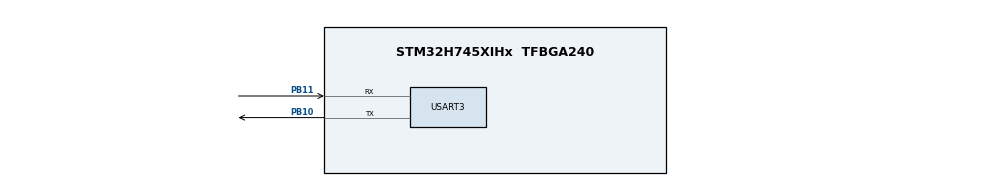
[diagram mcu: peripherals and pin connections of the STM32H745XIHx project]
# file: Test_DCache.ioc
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CortexM4.IPs=FATFS_M4\:I,FREERTOS_M4\:I,IWDG2\:I,RCC,USB_DEVICE_M4\:I,USB_HOST_M4\:I,WWDG2\:I,DMA,BDMA,MDMA,NVIC2\:I,SAI2\:I,LTDC\:I,SAI4\:I,DEBUG,PDM2PCM_M4\:I,PWR,RESMGR_UTILITY,SYS_M4\:I,CORTEX_M4\:I,OPENAMP_M4\:I,VREFBUF,GPIO
CortexM7.IPs=FATFS_M7\:I,FREERTOS_M7\:I,IWDG1\:I,RCC\:I,USB_DEVICE_M7\:I,USB_HOST_M7\:I,WWDG1\:I,DMA\:I,BDMA\:I,MDMA\:I,NVIC1\:I,CORTEX_M7\:I,DEBUG\:I,PDM2PCM_M7\:I,PWR\:I,RESMGR_UTILITY\:I,SYS\:I,OPENAMP_M7\:I,VREFBUF\:I,GPIO\:I,USART3\:I
Dma.MEMTOMEM.0.Direction=DMA_MEMORY_TO_MEMORY
Dma.MEMTOMEM.0.EventEnable=DISABLE
Dma.MEMTOMEM.0.FIFOMode=DMA_FIFOMODE_ENABLE
Dma.MEMTOMEM.0.FIFOThreshold=DMA_FIFO_THRESHOLD_FULL
Dma.MEMTOMEM.0.Instance=DMA1_Stream0
Dma.MEMTOMEM.0.MemBurst=DMA_MBURST_SINGLE
Dma.MEMTOMEM.0.MemDataAlignment=DMA_MDATAALIGN_WORD
Dma.MEMTOMEM.0.MemInc=DMA_MINC_ENABLE
Dma.MEMTOMEM.0.Mode=DMA_NORMAL
Dma.MEMTOMEM.0.PeriphBurst=DMA_PBURST_SINGLE
Dma.MEMTOMEM.0.PeriphDataAlignment=DMA_PDATAALIGN_WORD
Dma.MEMTOMEM.0.PeriphInc=DMA_PINC_ENABLE
Dma.MEMTOMEM.0.Polarity=HAL_DMAMUX_REQ_GEN_RISING
Dma.MEMTOMEM.0.Priority=DMA_PRIORITY_HIGH
Dma.MEMTOMEM.0.RequestNumber=1
Dma.MEMTOMEM.0.SignalID=NONE
Dma.MEMTOMEM.0.SyncEnable=DISABLE
Dma.MEMTOMEM.0.SyncPolarity=HAL_DMAMUX_SYNC_NO_EVENT
Dma.MEMTOMEM.0.SyncRequestNumber=1
Dma.MEMTOMEM.0.SyncSignalID=NONE
Dma.Request0=MEMTOMEM
Mcu.Family=STM32H7
Mcu.Name=STM32H745XIHx
Mcu.Package=TFBGA240
NVIC1.PriorityGroup=NVIC_PRIORITYGROUP_4
NVIC2.PriorityGroup=NVIC_PRIORITYGROUP_4
PB10.Mode=Asynchronous
PB10.PinAttribute=CortexM7
PB10.Signal=USART3_TX
PB11.Mode=Asynchronous
PB11.PinAttribute=CortexM7
PB11.Signal=USART3_RX
PH0-OSC_IN\ (PH0).Mode=HSE-External-Clock-Source
PH0-OSC_IN\ (PH0).PinAttribute=Free
PH0-OSC_IN\ (PH0).Signal=RCC_OSC_IN
ProjectManager.HeapSize=M4-0x200,M7-0x200
ProjectManager.StackSize=M4-0x400,M7-0x400
ProjectManager.TargetToolchain=STM32CubeIDE
RCC.ADCFreq_Value=50390625
RCC.APB1Freq_Value=25000000
RCC.APB2Freq_Value=25000000
RCC.APB3Freq_Value=25000000
RCC.APB4Freq_Value=25000000
RCC.CortexFreq_Value=25000000
RCC.DIVM1=23
RCC.DIVN1=177
RCC.DIVN3=192
RCC.DIVQ1=4
RCC.DIVR1=4
RCC.HCLKFreq_Value=25000000
RCC.PLL2FRACN=0
RCC.PLL3FRACN=0
RCC.PLLFRACN=0
RCC.PLLSourceVirtual=RCC_PLLSOURCE_HSE
RCC.PWR_Regulator_Voltage_Scale=PWR_REGULATOR_VOLTAGE_SCALE2
RCC.SYSCLKFreq_VALUE=25000000
RCC.SYSCLKSource=RCC_SYSCLKSOURCE_HSE
RCC.SupplySource=PWR_DIRECT_SMPS_SUPPLY
RCC.USBFreq_Value=48097826.086956516
USART3.VirtualMode-Asynchronous=VM_ASYNC
VP_SYS_M4_VS_Systick.Mode=SysTick
board=STM32H745I-DISCO

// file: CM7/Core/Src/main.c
/* USER CODE BEGIN Header */
/**
  ******************************************************************************
  * @file           : main.c
  * @brief          : Main program body
  ******************************************************************************
  * @attention
  *
  * Copyright (c) 2025 STMicroelectronics.
  * All rights reserved.
  *
  * This software is licensed under terms that can be found in the LICENSE file
  * in the root directory of this software component.
  * If no LICENSE file comes with this software, it is provided AS-IS.
  *
  ******************************************************************************
  */
/* USER CODE END Header */
#include "main.h"

/* USER CODE BEGIN Includes */
#include <stdio.h>
/* USER CODE END Includes */

/* USER CODE BEGIN PD */

#ifndef HSEM_ID_0
#define HSEM_ID_0 (0U) /* HW semaphore 0*/
#endif

/* USER CODE END PD */

/* USER CODE BEGIN PM */
#define BUFFER_SIZE 128
uint32_t src_buffer[BUFFER_SIZE];
uint32_t dst_buffer[BUFFER_SIZE];
/* USER CODE END PM */

UART_HandleTypeDef huart3;

DMA_HandleTypeDef hdma_memtomem_dma1_stream0;

void SystemClock_Config(void);
static void MX_GPIO_Init(void);
static void MX_DMA_Init(void);
static void MX_USART3_UART_Init(void);

/* USER CODE BEGIN 0 */
void fill_src_buffer(void)
{
    for (int i = 0; i < BUFFER_SIZE; i++)
        src_buffer[i] = i;
}
/* USER CODE END 0 */

int main(void)
{

/* USER CODE BEGIN Boot_Mode_Sequence_0 */
  //int32_t timeout;
/* USER CODE END Boot_Mode_Sequence_0 */

/* USER CODE BEGIN Boot_Mode_Sequence_1 */
  /* Wait until CPU2 boots and enters in stop mode or timeout*/
/*  timeout = 0xFFFF;
  while((__HAL_RCC_GET_FLAG(RCC_FLAG_D2CKRDY) != RESET) && (timeout-- > 0));
  if ( timeout < 0 )
  {
  Error_Handler();
  }*/
/* USER CODE END Boot_Mode_Sequence_1 */
  /* MCU Configuration--------------------------------------------------------*/

  /* Reset of all peripherals, Initializes the Flash interface and the Systick. */
  HAL_Init();

  /* Configure the system clock */
  SystemClock_Config();
/* USER CODE BEGIN Boot_Mode_Sequence_2 */
/* When system initialization is finished, Cortex-M7 will release Cortex-M4 by means of
HSEM notification */
/*HW semaphore Clock enable*/
__HAL_RCC_HSEM_CLK_ENABLE();
/*Take HSEM */
HAL_HSEM_FastTake(HSEM_ID_0);
/*Release HSEM in order to notify the CPU2(CM4)*/
HAL_HSEM_Release(HSEM_ID_0,0);
/* wait until CPU2 wakes up from stop mode */
/*timeout = 0xFFFF;
while((__HAL_RCC_GET_FLAG(RCC_FLAG_D2CKRDY) == RESET) && (timeout-- > 0));
if ( timeout < 0 )
{
Error_Handler();
}*/
/* USER CODE END Boot_Mode_Sequence_2 */

  /* Initialize all configured peripherals */
  MX_GPIO_Init();
  MX_DMA_Init();
  MX_USART3_UART_Init();
  /* USER CODE BEGIN 2 */

  char msg[100];
  	  // Enable D-Cache
      SCB_EnableDCache();

      fill_src_buffer();
      SCB_CleanDCache();
      // Problematic case: CPU has written the data but it's still in the cache
      // DMA reads the old data from SRAM

      HAL_DMA_Start(& hdma_memtomem_dma1_stream0, (uint32_t)src_buffer, (uint32_t)dst_buffer, BUFFER_SIZE);
      HAL_DMA_PollForTransfer(& hdma_memtomem_dma1_stream0, HAL_DMA_FULL_TRANSFER, HAL_MAX_DELAY);

      // There is a potential mismatch here

      for (int i = 0; i < BUFFER_SIZE; i++)
      {
          if (src_buffer[i] != dst_buffer[i])
          {
        	  sprintf(msg, "ERR\r\n");
        	  HAL_UART_Transmit(&huart3, (uint8_t*)msg, strlen(msg), HAL_MAX_DELAY);
          }
      }

      /*
      // Solution: Clean the cache before DMA
      SCB_CleanDCache();

      // Retry the transfer
      HAL_DMA_Start(&hdma_memtomem_dma1_stream0, (uint32_t)src_buffer, (uint32_t)dst_buffer, BUFFER_SIZE);
	  HAL_DMA_PollForTransfer(&hdma_memtomem_dma1_stream0, HAL_DMA_FULL_TRANSFER, HAL_MAX_DELAY);

	  // This time the data is transferred correctly
*/

  /* USER CODE END 2 */

  /* Infinite loop */
  while (1)
  {

  }
}

void SystemClock_Config(void)
{
  RCC_OscInitTypeDef RCC_OscInitStruct = {0};
  RCC_ClkInitTypeDef RCC_ClkInitStruct = {0};

  /** Supply configuration update enable
  */
  HAL_PWREx_ConfigSupply(PWR_DIRECT_SMPS_SUPPLY);

  /** Configure the main internal regulator output voltage
  */
  __HAL_PWR_VOLTAGESCALING_CONFIG(PWR_REGULATOR_VOLTAGE_SCALE2);

  while(!__HAL_PWR_GET_FLAG(PWR_FLAG_VOSRDY)) {}

  /** Initializes the RCC Oscillators according to the specified parameters
  * in the RCC_OscInitTypeDef structure.
  */
  RCC_OscInitStruct.OscillatorType = RCC_OSCILLATORTYPE_HSE;
  RCC_OscInitStruct.HSEState = RCC_HSE_BYPASS;
  RCC_OscInitStruct.PLL.PLLState = RCC_PLL_NONE;
  if (HAL_RCC_OscConfig(&RCC_OscInitStruct) != HAL_OK)
  {
    Error_Handler();
  }

  /** Initializes the CPU, AHB and APB buses clocks
  */
  RCC_ClkInitStruct.ClockType = RCC_CLOCKTYPE_HCLK|RCC_CLOCKTYPE_SYSCLK
                              |RCC_CLOCKTYPE_PCLK1|RCC_CLOCKTYPE_PCLK2
                              |RCC_CLOCKTYPE_D3PCLK1|RCC_CLOCKTYPE_D1PCLK1;
  RCC_ClkInitStruct.SYSCLKSource = RCC_SYSCLKSOURCE_HSE;
  RCC_ClkInitStruct.SYSCLKDivider = RCC_SYSCLK_DIV1;
  RCC_ClkInitStruct.AHBCLKDivider = RCC_HCLK_DIV1;
  RCC_ClkInitStruct.APB3CLKDivider = RCC_APB3_DIV1;
  RCC_ClkInitStruct.APB1CLKDivider = RCC_APB1_DIV1;
  RCC_ClkInitStruct.APB2CLKDivider = RCC_APB2_DIV1;
  RCC_ClkInitStruct.APB4CLKDivider = RCC_APB4_DIV1;

  if (HAL_RCC_ClockConfig(&RCC_ClkInitStruct, FLASH_LATENCY_0) != HAL_OK)
  {
    Error_Handler();
  }
}

static void MX_USART3_UART_Init(void)
{

  huart3.Instance = USART3;
  huart3.Init.BaudRate = 115200;
  huart3.Init.WordLength = UART_WORDLENGTH_8B;
  huart3.Init.StopBits = UART_STOPBITS_1;
  huart3.Init.Parity = UART_PARITY_NONE;
  huart3.Init.Mode = UART_MODE_TX_RX;
  huart3.Init.HwFlowCtl = UART_HWCONTROL_NONE;
  huart3.Init.OverSampling = UART_OVERSAMPLING_16;
  huart3.Init.OneBitSampling = UART_ONE_BIT_SAMPLE_DISABLE;
  huart3.Init.ClockPrescaler = UART_PRESCALER_DIV1;
  huart3.AdvancedInit.AdvFeatureInit = UART_ADVFEATURE_NO_INIT;
  if (HAL_UART_Init(&huart3) != HAL_OK)
  {
    Error_Handler();
  }
  if (HAL_UARTEx_SetTxFifoThreshold(&huart3, UART_TXFIFO_THRESHOLD_1_8) != HAL_OK)
  {
    Error_Handler();
  }
  if (HAL_UARTEx_SetRxFifoThreshold(&huart3, UART_RXFIFO_THRESHOLD_1_8) != HAL_OK)
  {
    Error_Handler();
  }
  if (HAL_UARTEx_DisableFifoMode(&huart3) != HAL_OK)
  {
    Error_Handler();
  }

}

static void MX_DMA_Init(void)
{

  /* DMA controller clock enable */
  __HAL_RCC_DMA1_CLK_ENABLE();

  /* Configure DMA request hdma_memtomem_dma1_stream0 on DMA1_Stream0 */
  hdma_memtomem_dma1_stream0.Instance = DMA1_Stream0;
  hdma_memtomem_dma1_stream0.Init.Request = DMA_REQUEST_MEM2MEM;
  hdma_memtomem_dma1_stream0.Init.Direction = DMA_MEMORY_TO_MEMORY;
  hdma_memtomem_dma1_stream0.Init.PeriphInc = DMA_PINC_ENABLE;
  hdma_memtomem_dma1_stream0.Init.MemInc = DMA_MINC_ENABLE;
  hdma_memtomem_dma1_stream0.Init.PeriphDataAlignment = DMA_PDATAALIGN_WORD;
  hdma_memtomem_dma1_stream0.Init.MemDataAlignment = DMA_MDATAALIGN_WORD;
  hdma_memtomem_dma1_stream0.Init.Mode = DMA_NORMAL;
  hdma_memtomem_dma1_stream0.Init.Priority = DMA_PRIORITY_HIGH;
  hdma_memtomem_dma1_stream0.Init.FIFOMode = DMA_FIFOMODE_ENABLE;
  hdma_memtomem_dma1_stream0.Init.FIFOThreshold = DMA_FIFO_THRESHOLD_FULL;
  hdma_memtomem_dma1_stream0.Init.MemBurst = DMA_MBURST_SINGLE;
  hdma_memtomem_dma1_stream0.Init.PeriphBurst = DMA_PBURST_SINGLE;
  if (HAL_DMA_Init(&hdma_memtomem_dma1_stream0) != HAL_OK)
  {
    Error_Handler( );
  }

}

static void MX_GPIO_Init(void)
{

  /* GPIO Ports Clock Enable */
  __HAL_RCC_GPIOB_CLK_ENABLE();

}

void Error_Handler(void)
{
  __disable_irq();
  while (1)
  {
  }
}
